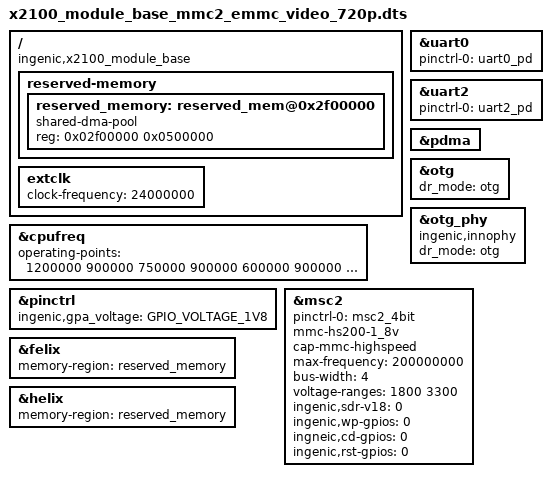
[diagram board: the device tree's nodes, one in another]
/dts-v1/;

#include <dt-bindings/input/input.h>
#include "x2100.dtsi"
#include <dt-bindings/interrupt-controller/irq.h>
#include <generated/autoconf.h>

/ {
	compatible = "ingenic,x2100_module_base", "ingenic,x2100";

	reserved-memory {
		#address-cells = <1>;
		#size-cells = <1>;
		ranges =<>;

		reserved_memory: reserved_mem@0x2f00000{
		      compatible = "shared-dma-pool";
		      reg = <0x02f00000 0x0500000>;
		};
	};
};

&uart0 {
	status = "okay";
	pinctrl-names = "default";
	pinctrl-0 = <&uart0_pd>;
};

&uart2 {
	status = "okay";
	pinctrl-names = "default";
	pinctrl-0 = <&uart2_pd>;
};

&cpufreq {
	status = "okay";
	operating-points = <
		/*KHZ uV */
		1200000	900000
		750000	900000
		600000	900000
		500000	900000
		400000	900000
		375000	900000
		300000	900000
		200000	900000
			>;

};

&pinctrl {
	ingenic,gpa_voltage = <GPIO_VOLTAGE_1V8>;
};

&pdma {
	status = "okay";
};

&otg {
	// g-use-dma;
	dr_mode = "otg";
	status = "okay";
};

&otg_phy {
	dr_mode = "otg";
	compatible = "ingenic,innophy", "syscon";
	status = "okay";
};

/* 原理图里写的是msc1 设备树配置是msc2 */
&msc2 {
	status = "okay";
	pinctrl-names ="default";
	pinctrl-0 = <&msc2_4bit>;
	mmc-hs200-1_8v;
	cap-mmc-highspeed;
	/* sd-uhs-sdr104; */
	/* cd-inverted; */
	max-frequency = <200000000>;
	bus-width = <4>;
	voltage-ranges = <1800 3300>;

	/* special property */
	ingenic,sdr-v18 = <0>;
	ingenic,wp-gpios = <0>;
	ingneic,cd-gpios = <0>;
	ingenic,rst-gpios = <0>;
};

&felix {
	status = "okay";
	memory-region=<&reserved_memory>;
};

&helix {
	status = "okay";
	memory-region=<&reserved_memory>;
};

/ {

	extclk: extclk {
		clock-frequency = <24000000>;
	};

	};
